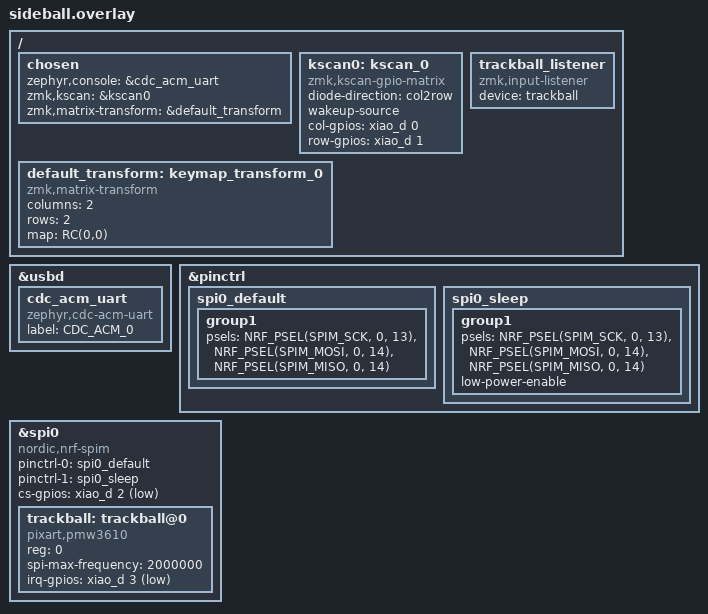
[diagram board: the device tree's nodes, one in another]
#include <zephyr/dt-bindings/input/input-event-codes.h>
#include <dt-bindings/zmk/matrix_transform.h>

&usbd {
    status = "okay";
    cdc_acm_uart: cdc_acm_uart {
		compatible = "zephyr,cdc-acm-uart";
		label = "CDC_ACM_0";
	};
};

&pinctrl {
        spi0_default: spi0_default {
            group1 {
                psels = <NRF_PSEL(SPIM_SCK, 0, 13)>,
                    <NRF_PSEL(SPIM_MOSI, 0, 14)>,
                    <NRF_PSEL(SPIM_MISO, 0, 14)>;
            };
        };

        spi0_sleep: spi0_sleep {
            group1 {
                psels = <NRF_PSEL(SPIM_SCK, 0, 13)>,
                    <NRF_PSEL(SPIM_MOSI, 0, 14)>,
                    <NRF_PSEL(SPIM_MISO, 0, 14)>;
                low-power-enable;
            };
        };
    };

&spi0 {
    status = "okay";
    compatible = "nordic,nrf-spim";
    pinctrl-0 = <&spi0_default>;
    pinctrl-1 = <&spi0_sleep>;
    pinctrl-names = "default", "sleep";
    cs-gpios = <&xiao_d 2 GPIO_ACTIVE_LOW>;

    trackball: trackball@0 {
        status = "okay";
        compatible = "pixart,pmw3610";
        reg = <0>;
        spi-max-frequency = <2000000>;
        irq-gpios = <&xiao_d 3 (GPIO_ACTIVE_LOW | GPIO_PULL_UP)>;
        // badjeff cpi = <2000>;
        // badjeff evt-type = <INPUT_EV_REL>;
        // badjeff x-input-code = <INPUT_REL_X>;
        // badjeff y-input-code = <INPUT_REL_Y>;
    };
};

/ {
    chosen {
        zephyr,console = &cdc_acm_uart;
        zmk,kscan = &kscan0;
        zmk,matrix-transform = &default_transform;
    };

    kscan0: kscan_0 {
        compatible = "zmk,kscan-gpio-matrix";
        diode-direction = "col2row";
        wakeup-source;

        col-gpios = <&xiao_d 0 GPIO_ACTIVE_HIGH>;

        row-gpios = <&xiao_d 1 (GPIO_ACTIVE_HIGH | GPIO_PULL_DOWN)>;
    };

    default_transform: keymap_transform_0 {
        compatible = "zmk,matrix-transform";
        columns = <2>;
        rows = <2>;

        map = <RC(0,0)>;
    };
};

/ {
    trackball_listener {
        compatible = "zmk,input-listener";
        device = <&trackball>;
    };
};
